AUTOSAR XML (schema 4-0-3)
standard types defined: UInt32, UInt8
package /AUTOSAR_Platform/DataConstrs
  range DC_UInt8: raw 0..255
package /PATAC/MSM/ComponentTypes
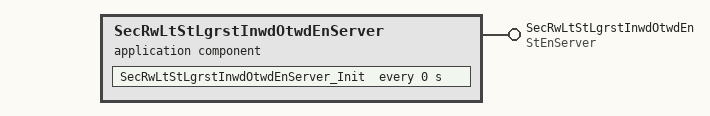
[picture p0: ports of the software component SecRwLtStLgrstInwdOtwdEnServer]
  application sw component type SecRwLtStLgrstInwdOtwdEnServer
    provide port SecRwLtStLgrstInwdOtwdEn: provided-com-specs=[{operation=Clear, queue-length=1}, {operation=Get, queue-length=1}, {operation=Set, queue-length=1}], provided-interface=StEnServer
    behavior SecRwLtStLgrstInwdOtwdEnServer_InternalBehavior
      operation invoked event OIT_SecRwLtStLgrstInwdOtwdEn_Clear_SecRwLtStLgrstInwdOtwdEn_Clear: start-on-event=SecRwLtStLgrstInwdOtwdEn_Clear, operation=SecRwLtStLgrstInwdOtwdEn.Clear
      operation invoked event OIT_SecRwLtStLgrstInwdOtwdEn_Get_SecRwLtStLgrstInwdOtwdEn_Get: start-on-event=SecRwLtStLgrstInwdOtwdEn_Get, operation=SecRwLtStLgrstInwdOtwdEn.Get
      operation invoked event OIT_SecRwLtStLgrstInwdOtwdEn_Set_SecRwLtStLgrstInwdOtwdEn_Set: start-on-event=SecRwLtStLgrstInwdOtwdEn_Set, operation=SecRwLtStLgrstInwdOtwdEn.Set
      timing event SecRwLtStLgrstInwdOtwdEnServer_InitEvent: start-on-event=SecRwLtStLgrstInwdOtwdEnServer_Init, period=0
      4 x runnable:
        SecRwLtStLgrstInwdOtwdEn_Clear
        SecRwLtStLgrstInwdOtwdEn_Get
        SecRwLtStLgrstInwdOtwdEn_Set
        SecRwLtStLgrstInwdOtwdEnServer_Init
  swc implementation SecRwLtStLgrstInwdOtwdEnServer_Implementation: behavior=SecRwLtStLgrstInwdOtwdEnServer_InternalBehavior
    code-descriptors:
      code Default: artifact-descriptors=autosar-engineering-object={short-label=Default, category=SWSRC}
package /PATAC/MSM/ModeAdjust/PortInterface
  client server interface StEnServer
    operation Clear
      arg data: type=UInt8, direction=IN, server-argument-impl-policy=USE-ARGUMENT-TYPE
    operation Get
      arg data: type=UInt32, direction=OUT, server-argument-impl-policy=USE-ARGUMENT-TYPE
    operation Set
      arg data: type=UInt8, direction=IN, server-argument-impl-policy=USE-ARGUMENT-TYPE
